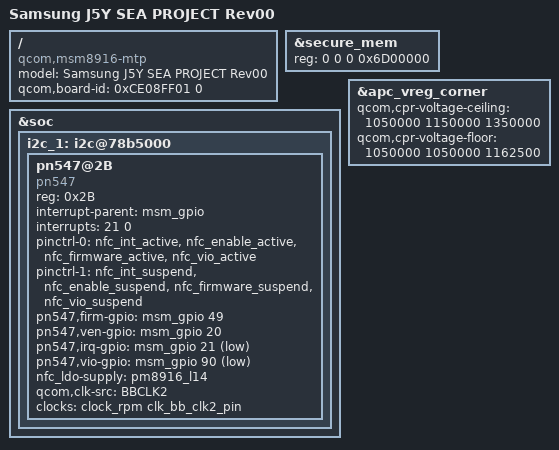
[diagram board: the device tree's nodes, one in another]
/* Copyright (c) 2014, The Linux Foundation. All rights reserved.
*
* This program is free software; you can redistribute it and/or modify
* it under the terms of the GNU General Public License version 2 and
* only version 2 as published by the Free Software Foundation.
*
* This program is distributed in the hope that it will be useful,
* but WITHOUT ANY WARRANTY; without even the implied warranty of
* MERCHANTABILITY or FITNESS FOR A PARTICULAR PURPOSE.  See the
* GNU General Public License for more details.
*/

/dts-v1/;

#include "msm8916-sec-j5lte-eur-r00.dtsi"
#include "msm8916-memory.dtsi"

/ {
	model = "Samsung J5Y SEA PROJECT Rev00";
	compatible = "qcom,msm8916-mtp", "qcom,msm8916", "qcom,mtp";
	/*QCOM BOARD REV TYPE...*/
	/*qcom,board-id = <8 0>;*/
	/*SEC BOARD REV TYPE...*/
	qcom,board-id = <0xCE08FF01 0>;
        /*parm1)[31:24]platform_id [23:16]qc_hw_id [15:8]national code [7:0] operator, param2)SEC hw-rev*/
};

&secure_mem {
	reg = <0 0 0 0x6D00000>;
};
&soc {
	i2c_1: i2c@78b5000 { /* BLSP1 QUP1 */
		status="ok";
		pn547@2B {
			compatible = "pn547";
			reg = <0x2B>;
			interrupt-parent = <&msm_gpio>;
			interrupts = <21 0>;
			pinctrl-names = "nfc_active","nfc_suspend";
			pinctrl-0 = <&nfc_int_active &nfc_enable_active &nfc_firmware_active &nfc_vio_active>;
			pinctrl-1 = <&nfc_int_suspend &nfc_enable_suspend &nfc_firmware_suspend &nfc_vio_suspend>;
			pn547,firm-gpio = <&msm_gpio 49 0x00>;
			pn547,ven-gpio = <&msm_gpio 20 0x00>;
			pn547,irq-gpio = <&msm_gpio 21 0x01>;
			pn547,vio-gpio = <&msm_gpio 90 0x01>;
			nfc_ldo-supply = <&pm8916_l14>;
			qcom,clk-src = "BBCLK2";
			clocks = <&clock_rpm clk_bb_clk2_pin>;
			clock-names = "nfc_clock";
		};
	};
};

/*overwrite s2 cpr voltage for model variant*/
&apc_vreg_corner {
        qcom,cpr-voltage-ceiling = <1050000 1150000 1350000>;
        qcom,cpr-voltage-floor = <1050000 1050000 1162500>;
};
